# HDSC_HC32M424 register map
Vendor: HDSC; Series: ARMCM4; File version: 1.0
CPU: CM4 r0p1, little endian, MPU, FPU, 4 interrupt priority bits
Registers are 32-bit, read-write, reset 0x0 unless marked. A register's access mark holds for its fields unless they carry their own. Offsets are from the block's base; [hi:lo] are bit positions; {n}, {i} and the like mark numbered series.

## EFM
Base 0x40010400
0x00 FAPRT
  [15:0] FAPRT
0x04 FSTP
  [0] FSTP
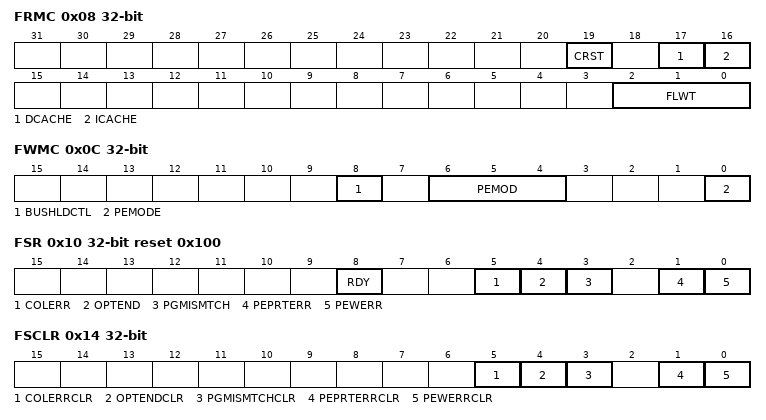
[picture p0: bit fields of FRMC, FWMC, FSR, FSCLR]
0x08 FRMC
  [19] CRST, [17] DCACHE, [16] ICACHE, [2:0] FLWT
0x0C FWMC
  [8] BUSHLDCTL, [6:4] PEMOD, [0] PEMODE
0x10 FSR ro reset 0x100
  [8] RDY, [5] COLERR, [4] OPTEND, [3] PGMISMTCH, [1] PEPRTERR, [0] PEWERR
0x14 FSCLR
  [5] COLERRCLR, [4] OPTENDCLR, [3] PGMISMTCHCLR, [1] PEPRTERRCLR, [0] PEWERRCLR
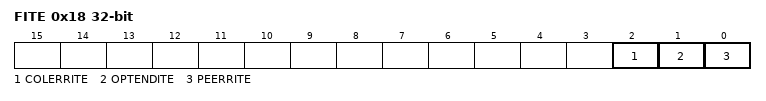
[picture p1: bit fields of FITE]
0x18 FITE
  [2] COLERRITE, [1] OPTENDITE, [0] PEERRITE
0x20 FPMTSW
  [17:0] FPMTSW
0x24 FPMTEW
  [17:0] FPMTEW
{0x50+4i} UQID{i} ro (i=0..3)
0x288 HRCCFGR 8-bit
  [3:0] HRCFREQS

## EMB0 — desc EMB
Base 0x40017C00
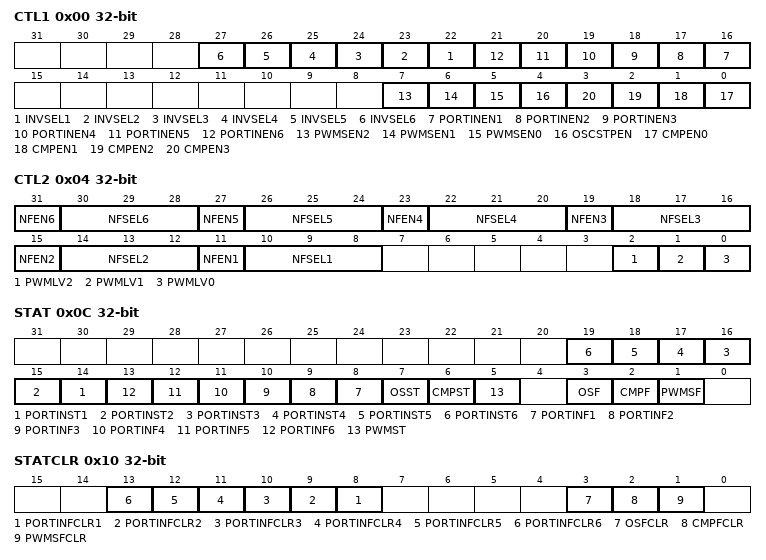
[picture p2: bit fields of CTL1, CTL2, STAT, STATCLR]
0x00 CTL1
  [n+21] INVSEL{n} (n=1..6), [n+15] PORTINEN{n} (n=1..6), [7] PWMSEN2, [6] PWMSEN1, [5] PWMSEN0, [4] OSCSTPEN, [n] CMPEN{n} (n=0..3)
0x04 CTL2
  [4n+7] NFEN{n} (n=1..6), [4n+6:4n+4] NFSEL{n} (n=1..6), [2] PWMLV2, [1] PWMLV1, [0] PWMLV0
0x08 SOE
  [0] SOE
0x0C STAT ro
  [n+13] PORTINST{n} rw (n=1..6), [n+7] PORTINF{n} (n=1..6), [7] OSST, [6] CMPST, [5] PWMST, [3] OSF, [2] CMPF, [1] PWMSF
0x10 STATCLR wo
  [n+7] PORTINFCLR{n} (n=1..6), [3] OSFCLR, [2] CMPFCLR, [1] PWMSFCLR
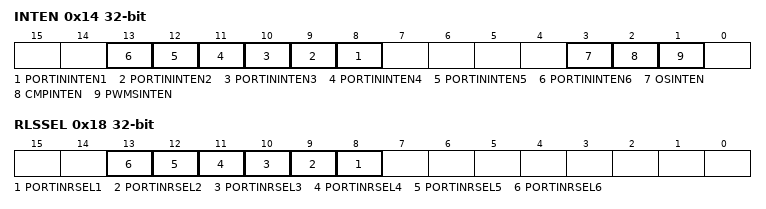
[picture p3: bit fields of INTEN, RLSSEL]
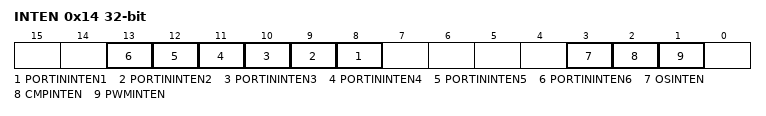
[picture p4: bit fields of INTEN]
0x14 INTEN
  [n+7] PORTININTEN{n} (n=1..6), [3] OSINTEN, [2] CMPINTEN, [1] PWMSINTEN
0x18 RLSSEL
  [n+7] PORTINRSEL{n} (n=1..6)

## EMB1 — desc EMB
Base 0x40017C20
Registers as EMB0; these are added or differ:
0x14 INTEN
  [n+7] PORTININTEN{n} (n=1..6), [3] OSINTEN, [2] CMPINTEN, [1] PWMINTEN

## EMB2 — desc EMB
Base 0x40017C40
Same registers: EMB3 0x40017C60
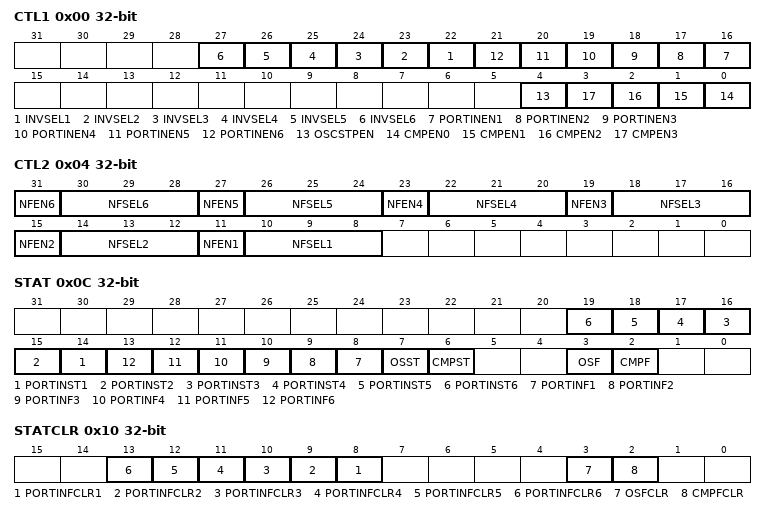
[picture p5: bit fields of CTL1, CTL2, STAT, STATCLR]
0x00 CTL1
  [n+21] INVSEL{n} (n=1..6), [n+15] PORTINEN{n} (n=1..6), [4] OSCSTPEN, [n] CMPEN{n} (n=0..3)
0x04 CTL2
  [4n+7] NFEN{n} (n=1..6), [4n+6:4n+4] NFSEL{n} (n=1..6)
0x08 SOE
  [0] SOE
0x0C STAT ro
  [n+13] PORTINST{n} rw (n=1..6), [n+7] PORTINF{n} (n=1..6), [7] OSST, [6] CMPST, [3] OSF, [2] CMPF
0x10 STATCLR wo
  [n+7] PORTINFCLR{n} (n=1..6), [3] OSFCLR, [2] CMPFCLR
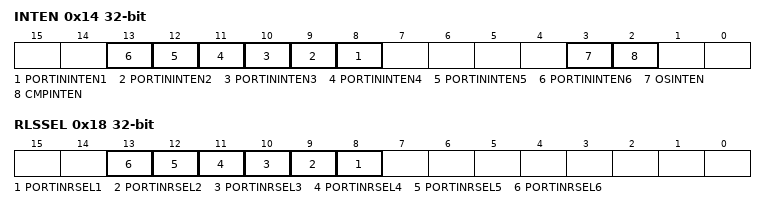
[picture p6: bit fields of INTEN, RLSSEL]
0x14 INTEN
  [n+7] PORTININTEN{n} (n=1..6), [3] OSINTEN, [2] CMPINTEN
0x18 RLSSEL
  [n+7] PORTINRSEL{n} (n=1..6)
0x1C ECSR
  [1:0] EMBVAL

## FCM
Base 0x40048400
0x00 LVR
  [15:0] LVR
0x04 UVR
  [15:0] UVR
0x08 CNTR ro
  [15:0] CNTR
0x0C STR
  [0] START
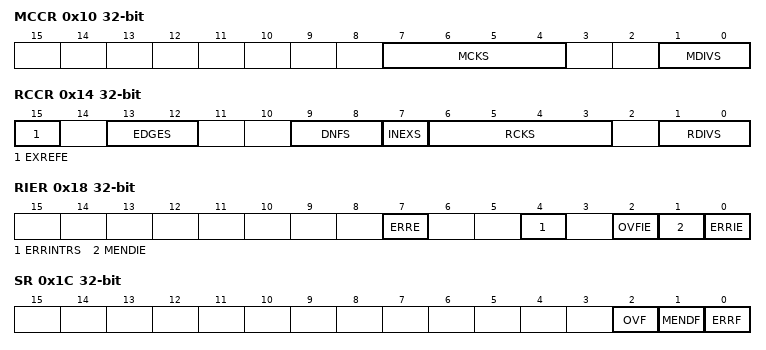
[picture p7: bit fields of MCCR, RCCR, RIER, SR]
0x10 MCCR
  [7:4] MCKS, [1:0] MDIVS
0x14 RCCR
  [15] EXREFE, [13:12] EDGES, [9:8] DNFS, [7] INEXS, [6:3] RCKS, [1:0] RDIVS
0x18 RIER
  [7] ERRE, [4] ERRINTRS, [2] OVFIE, [1] MENDIE, [0] ERRIE
0x1C SR ro
  [2] OVF, [1] MENDF, [0] ERRF
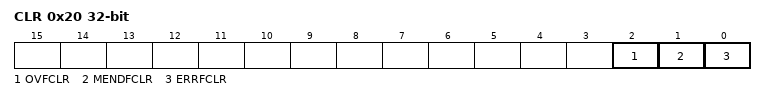
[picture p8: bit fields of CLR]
0x20 CLR wo
  [2] OVFCLR, [1] MENDFCLR, [0] ERRFCLR

## I2C
Base 0x4004E000
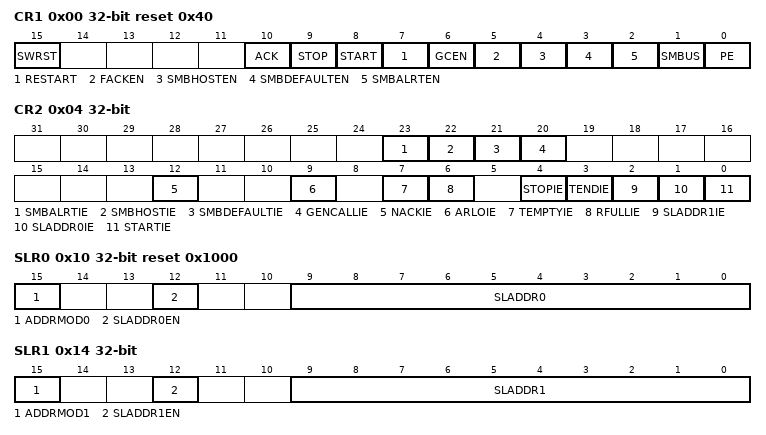
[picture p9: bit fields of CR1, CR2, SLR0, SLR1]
0x00 CR1 reset 0x40
  [15] SWRST, [10] ACK, [9] STOP, [8] START, [7] RESTART, [6] GCEN, [5] FACKEN, [4] SMBHOSTEN, [3] SMBDEFAULTEN, [2] SMBALRTEN, [1] SMBUS, [0] PE
0x04 CR2
  [23] SMBALRTIE, [22] SMBHOSTIE, [21] SMBDEFAULTIE, [20] GENCALLIE, [12] NACKIE, [9] ARLOIE, [7] TEMPTYIE, [6] RFULLIE, [4] STOPIE, [3] TENDIE, [2] SLADDR1IE, [1] SLADDR0IE, [0] STARTIE
0x0C CR4 reset 0x300307
  [10] BUSWAIT
0x10 SLR0 reset 0x1000
  [15] ADDRMOD0, [12] SLADDR0EN, [9:0] SLADDR0
0x14 SLR1
  [15] ADDRMOD1, [12] SLADDR1EN, [9:0] SLADDR1
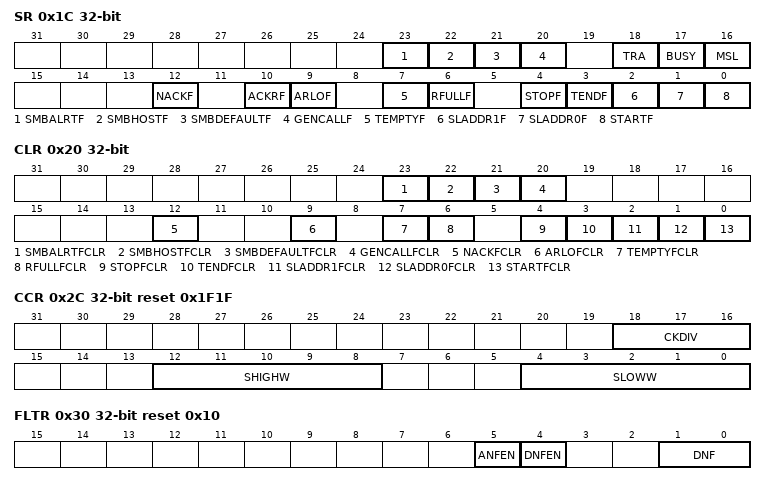
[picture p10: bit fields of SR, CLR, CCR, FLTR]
0x1C SR ro
  [23] SMBALRTF, [22] SMBHOSTF, [21] SMBDEFAULTF, [20] GENCALLF, [18] TRA rw, [17] BUSY, [16] MSL rw, [12] NACKF, [10] ACKRF, [9] ARLOF, [7] TEMPTYF, [6] RFULLF, [4] STOPF, [3] TENDF, [2] SLADDR1F, [1] SLADDR0F, [0] STARTF
0x20 CLR wo
  [23] SMBALRTFCLR, [22] SMBHOSTFCLR, [21] SMBDEFAULTFCLR, [20] GENCALLFCLR, [12] NACKFCLR, [9] ARLOFCLR, [7] TEMPTYFCLR, [6] RFULLFCLR, [4] STOPFCLR, [3] TENDFCLR, [2] SLADDR1FCLR, [1] SLADDR0FCLR, [0] STARTFCLR
0x24 DTR 8-bit reset 0xFF
  [7:0] DT
0x28 DRR 8-bit
  [7:0] DR
0x2C CCR reset 0x1F1F
  [18:16] CKDIV, [12:8] SHIGHW, [4:0] SLOWW
0x30 FLTR reset 0x10
  [5] ANFEN, [4] DNFEN, [1:0] DNF
